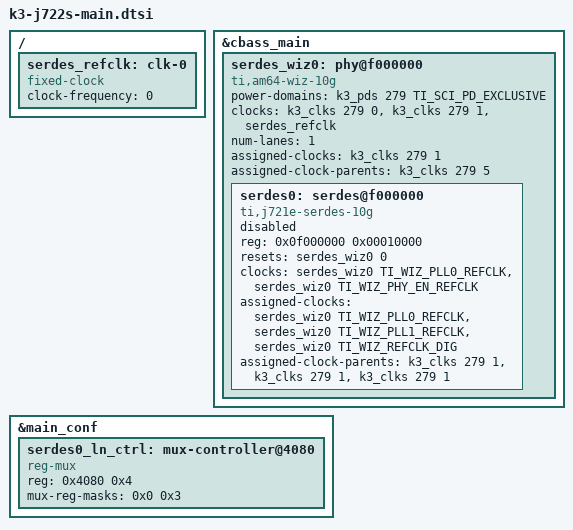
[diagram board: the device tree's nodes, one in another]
// SPDX-License-Identifier: GPL-2.0-only OR MIT
/*
 * Device Tree file for the J722S main domain peripherals
 * Copyright (C) 2023-2024 Texas Instruments Incorporated - https://www.ti.com/
 */

#include <dt-bindings/phy/phy-ti.h>

/ {
	serdes_refclk: clk-0 {
		compatible = "fixed-clock";
		#clock-cells = <0>;
		clock-frequency = <0>;
	};
};

&cbass_main {
	serdes_wiz0: phy@f000000 {
		compatible = "ti,am64-wiz-10g";
		ranges = <0x0f000000 0x0 0x0f000000 0x00010000>;
		#address-cells = <1>;
		#size-cells = <1>;
		power-domains = <&k3_pds 279 TI_SCI_PD_EXCLUSIVE>;
		clocks = <&k3_clks 279 0>, <&k3_clks 279 1>, <&serdes_refclk>;
		clock-names = "fck", "core_ref_clk", "ext_ref_clk";
		num-lanes = <1>;
		#reset-cells = <1>;
		#clock-cells = <1>;

		assigned-clocks = <&k3_clks 279 1>;
		assigned-clock-parents = <&k3_clks 279 5>;

		serdes0: serdes@f000000 {
			compatible = "ti,j721e-serdes-10g";
			reg = <0x0f000000 0x00010000>;
			reg-names = "torrent_phy";
			resets = <&serdes_wiz0 0>;
			reset-names = "torrent_reset";
			clocks = <&serdes_wiz0 TI_WIZ_PLL0_REFCLK>,
				 <&serdes_wiz0 TI_WIZ_PHY_EN_REFCLK>;
			clock-names = "refclk", "phy_en_refclk";
			assigned-clocks = <&serdes_wiz0 TI_WIZ_PLL0_REFCLK>,
					  <&serdes_wiz0 TI_WIZ_PLL1_REFCLK>,
					  <&serdes_wiz0 TI_WIZ_REFCLK_DIG>;
			assigned-clock-parents = <&k3_clks 279 1>,
						 <&k3_clks 279 1>,
						 <&k3_clks 279 1>;
			#address-cells = <1>;
			#size-cells = <0>;
			#clock-cells = <1>;

			status = "disabled"; /* Needs lane config */
		};
	};
};

&main_conf {
	serdes0_ln_ctrl: mux-controller@4080 {
		compatible = "reg-mux";
		reg = <0x4080 0x4>;
		#mux-control-cells = <1>;
		mux-reg-masks = <0x0 0x3>; /* SERDES0 lane0 select */
	};
};
